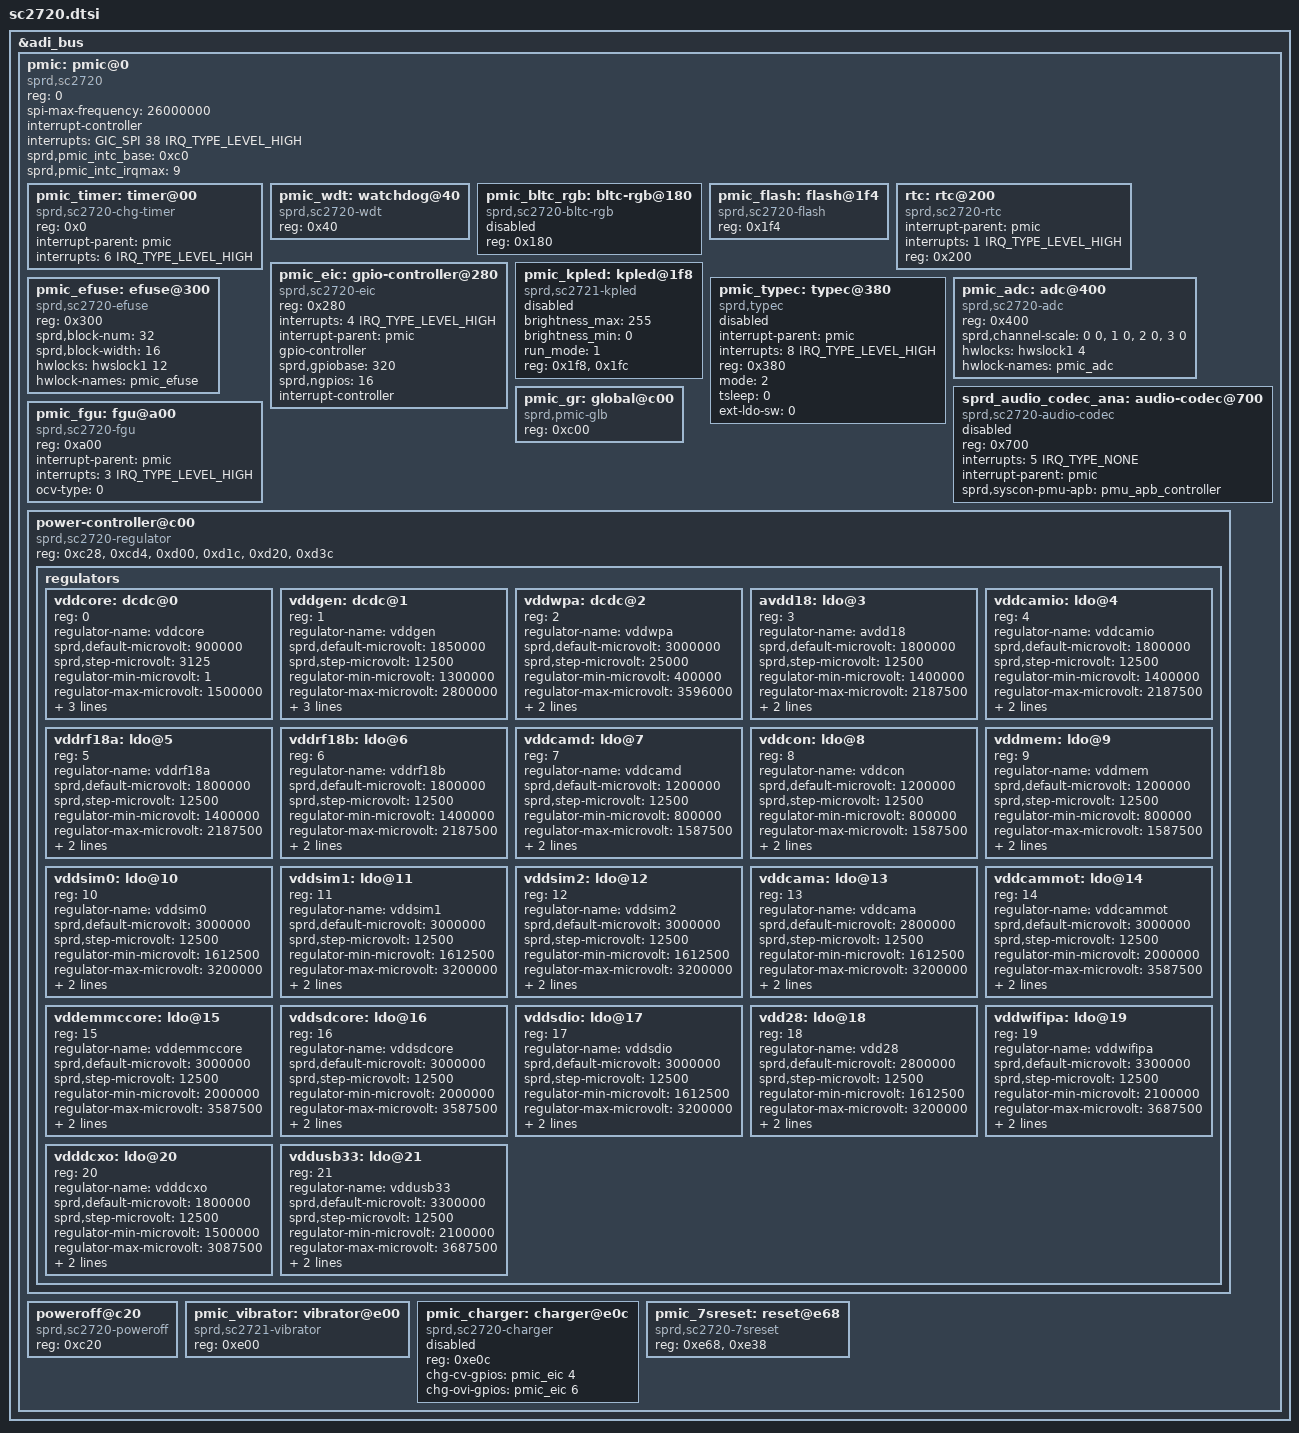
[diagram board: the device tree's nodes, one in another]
/*
 * Spreadtrum Analog Die SC2720 DTS file
 *
 * Copyright (C) 2017, Spreadtrum Communications Inc.
 *
 * This file is licensed under a dual GPLv2 or X11 license.
 */

&adi_bus {
	pmic: pmic@0 {
		compatible = "sprd,sc2720";
		reg = <0>; /* chip select 0 */
		spi-max-frequency = <26000000>;
		#address-cells = <1>;
		#size-cells = <0>;
		interrupt-controller;
		#interrupt-cells = <2>;
		interrupts = <GIC_SPI 38 IRQ_TYPE_LEVEL_HIGH>;
		sprd,pmic_intc_base = <0xc0>;
		sprd,pmic_intc_irqmax = <9>;

		pmic_timer: timer@00 {
			compatible = "sprd,sc2720-chg-timer";
			reg = <0x0>;
			interrupt-parent = <&pmic>;
			interrupts = <6 IRQ_TYPE_LEVEL_HIGH>;
		};

		pmic_wdt: watchdog@40 {
			compatible = "sprd,sc2720-wdt";
			reg = <0x40>;
		};

		pmic_bltc_rgb: bltc-rgb@180 {
			compatible = "sprd,sc2720-bltc-rgb";
			reg = <0x180>;
			status = "disabled";
		};

		pmic_flash: flash@1f4 {
			compatible = "sprd,sc2720-flash";
			reg = <0x1f4>;
			status = "okay";
		};

		rtc: rtc@200 {
			compatible = "sprd,sc2720-rtc";
			interrupt-parent = <&pmic>;
			interrupts = <1 IRQ_TYPE_LEVEL_HIGH>;
			reg = <0x200>;
		};

		pmic_eic: gpio-controller@280 {
			compatible = "sprd,sc2720-eic";
			reg = <0x280>;
			interrupts = <4 IRQ_TYPE_LEVEL_HIGH>;
			interrupt-parent = <&pmic>;
			gpio-controller;
			#gpio-cells = <2>;
			sprd,gpiobase = <320>;
			sprd,ngpios = <16>;
			interrupt-controller;
			#interrupt-cells = <2>;
		};

		pmic_kpled: kpled@1f8 {
			compatible = "sprd,sc2721-kpled";
			brightness_max = <255>;
			brightness_min = <0>;
			run_mode = <1>; /* default current mode */
			reg = <0x1f8>,<0x1fc>;
			status = "disabled";
		};

		pmic_efuse: efuse@300 {
			compatible = "sprd,sc2720-efuse";
			reg = <0x300>;
			sprd,block-num = <32>;
			sprd,block-width = <16>;
			hwlocks = <&hwslock1 12>;
			hwlock-names = "pmic_efuse";
		};

		pmic_typec: typec@380 {
		    compatible = "sprd,typec";
		    interrupt-parent = <&pmic>;
		    interrupts = <8 IRQ_TYPE_LEVEL_HIGH>;
		    reg = <0x380>;
		    mode = <2>;
		    tsleep = <0>;
		    ext-ldo-sw = <0>;
		    status = "disabled";
		};

		pmic_adc: adc@400{
			compatible = "sprd,sc2720-adc";
			reg = <0x400>;
			#io-channel-cells = <1>;
			sprd,channel-scale = <0 0>, <1 0>, <2 0>, <3 0>;
			hwlocks = <&hwslock1 4>;
			hwlock-names = "pmic_adc";
		};

		sprd_audio_codec_ana: audio-codec@700 {
			compatible = "sprd,sc2720-audio-codec";
			#sound-dai-cells = <1>;
			reg = <0x700>;
			interrupts = <5 IRQ_TYPE_NONE>;
			interrupt-parent = <&pmic>;
			sprd,syscon-pmu-apb = <&pmu_apb_controller>;
			status = "disabled";
		};

		pmic_fgu: fgu@a00 {
			compatible = "sprd,sc2720-fgu";
			reg = <0xa00>;
			interrupt-parent = <&pmic>;
			interrupts = <3 IRQ_TYPE_LEVEL_HIGH>;
			ocv-type = <0>;
		};

		pmic_gr: global@c00 {
			compatible = "sprd,pmic-glb";
			reg = <0xc00>;
		};

		power-controller@c00 {
			compatible = "sprd,sc2720-regulator";
			reg = <0xc28>,<0xcd4>,<0xd00>,<0xd1c>,<0xd20>,<0xd3c>;

			regulators {
				#address-cells = <1>;
				#size-cells = <0>;

				vddcore: dcdc@0 {
					reg = <0>;
					regulator-name = "vddcore";
					sprd,default-microvolt = <900000>;
					sprd,step-microvolt = <3125>;
					regulator-min-microvolt = <1>;
					regulator-max-microvolt = <1500000>;
					regulator-microvolt-offset = <0>;
					sprd,hide-offset = <1000>;
					sprd,default-on;
				};

				vddgen: dcdc@1 {
					reg = <1>;
					regulator-name = "vddgen";
					sprd,default-microvolt = <1850000>;
					sprd,step-microvolt = <12500>;
					regulator-min-microvolt = <1300000>;
					regulator-max-microvolt = <2800000>;
					regulator-microvolt-offset = <0>;
					sprd,hide-offset = <1000>;
					sprd,default-on;
				};

				vddwpa: dcdc@2 {
					reg = <2>;
					regulator-name = "vddwpa";
					sprd,default-microvolt = <3000000>;
					sprd,step-microvolt = <25000>;
					regulator-min-microvolt = <400000>;
					regulator-max-microvolt = <3596000>;
					regulator-microvolt-offset = <0>;
					sprd,hide-offset = <1000>;
				};

				avdd18: ldo@3 {
					reg = <3>;
					regulator-name = "avdd18";
					sprd,default-microvolt = <1800000>;
					sprd,step-microvolt = <12500>;
					regulator-min-microvolt = <1400000>;
					regulator-max-microvolt = <2187500>;
					regulator-microvolt-offset = <0>;
					sprd,hide-offset = <1000>;
				};

				vddcamio: ldo@4 {
					reg = <4>;
					regulator-name = "vddcamio";
					sprd,default-microvolt = <1800000>;
					sprd,step-microvolt = <12500>;
					regulator-min-microvolt = <1400000>;
					regulator-max-microvolt = <2187500>;
					regulator-microvolt-offset = <0>;
					sprd,hide-offset = <1000>;
				};

				vddrf18a: ldo@5 {
					reg = <5>;
					regulator-name = "vddrf18a";
					sprd,default-microvolt = <1800000>;
					sprd,step-microvolt = <12500>;
					regulator-min-microvolt = <1400000>;
					regulator-max-microvolt = <2187500>;
					regulator-microvolt-offset = <0>;
					sprd,hide-offset = <1000>;
				};

				vddrf18b: ldo@6 {
					reg = <6>;
					regulator-name = "vddrf18b";
					sprd,default-microvolt = <1800000>;
					sprd,step-microvolt = <12500>;
					regulator-min-microvolt = <1400000>;
					regulator-max-microvolt = <2187500>;
					regulator-microvolt-offset = <0>;
					sprd,hide-offset = <1000>;
				};

				vddcamd: ldo@7 {
					reg = <7>;
					regulator-name = "vddcamd";
					sprd,default-microvolt = <1200000>;
					sprd,step-microvolt = <12500>;
					regulator-min-microvolt = <800000>;
					regulator-max-microvolt = <1587500>;
					regulator-microvolt-offset = <0>;
					sprd,hide-offset = <1000>;
				};

				vddcon: ldo@8 {
					reg = <8>;
					regulator-name = "vddcon";
					sprd,default-microvolt = <1200000>;
					sprd,step-microvolt = <12500>;
					regulator-min-microvolt = <800000>;
					regulator-max-microvolt = <1587500>;
					regulator-microvolt-offset = <0>;
					sprd,hide-offset = <1000>;
				};

				vddmem: ldo@9 {
					reg = <9>;
					regulator-name = "vddmem";
					sprd,default-microvolt = <1200000>;
					sprd,step-microvolt = <12500>;
					regulator-min-microvolt = <800000>;
					regulator-max-microvolt = <1587500>;
					regulator-microvolt-offset = <0>;
					sprd,hide-offset = <1000>;
				};

				vddsim0: ldo@10 {
					reg = <10>;
					regulator-name = "vddsim0";
					sprd,default-microvolt = <3000000>;
					sprd,step-microvolt = <12500>;
					regulator-min-microvolt = <1612500>;
					regulator-max-microvolt = <3200000>;
					regulator-microvolt-offset = <0>;
					sprd,hide-offset = <1000>;
				};

				vddsim1: ldo@11 {
					reg = <11>;
					regulator-name = "vddsim1";
					sprd,default-microvolt = <3000000>;
					sprd,step-microvolt = <12500>;
					regulator-min-microvolt = <1612500>;
					regulator-max-microvolt = <3200000>;
					regulator-microvolt-offset = <0>;
					sprd,hide-offset = <1000>;
				};

				vddsim2: ldo@12 {
					reg = <12>;
					regulator-name = "vddsim2";
					sprd,default-microvolt = <3000000>;
					sprd,step-microvolt = <12500>;
					regulator-min-microvolt = <1612500>;
					regulator-max-microvolt = <3200000>;
					regulator-microvolt-offset = <0>;
					sprd,hide-offset = <1000>;
				};

				vddcama: ldo@13 {
					reg = <13>;
					regulator-name = "vddcama";
					sprd,default-microvolt = <2800000>;
					sprd,step-microvolt = <12500>;
					regulator-min-microvolt = <1612500>;
					regulator-max-microvolt = <3200000>;
					regulator-microvolt-offset = <0>;
					sprd,hide-offset = <1000>;
				};

				vddcammot: ldo@14 {
					reg = <14>;
					regulator-name = "vddcammot";
					sprd,default-microvolt = <3000000>;
					sprd,step-microvolt = <12500>;
					regulator-min-microvolt = <2000000>;
					regulator-max-microvolt = <3587500>;
					regulator-microvolt-offset = <0>;
					sprd,hide-offset = <1000>;
				};

				vddemmccore: ldo@15 {
					reg = <15>;
					regulator-name = "vddemmccore";
					sprd,default-microvolt = <3000000>;
					sprd,step-microvolt = <12500>;
					regulator-min-microvolt = <2000000>;
					regulator-max-microvolt = <3587500>;
					regulator-microvolt-offset = <0>;
					sprd,hide-offset = <1000>;
				};

				vddsdcore: ldo@16 {
					reg = <16>;
					regulator-name = "vddsdcore";
					sprd,default-microvolt = <3000000>;
					sprd,step-microvolt = <12500>;
					regulator-min-microvolt = <2000000>;
					regulator-max-microvolt = <3587500>;
					regulator-microvolt-offset = <0>;
					sprd,hide-offset = <1000>;
				};

				vddsdio: ldo@17 {
					reg = <17>;
					regulator-name = "vddsdio";
					sprd,default-microvolt = <3000000>;
					sprd,step-microvolt = <12500>;
					regulator-min-microvolt = <1612500>;
					regulator-max-microvolt = <3200000>;
					regulator-microvolt-offset = <0>;
					sprd,hide-offset = <1000>;
				};

				vdd28: ldo@18 {
					reg = <18>;
					regulator-name = "vdd28";
					sprd,default-microvolt = <2800000>;
					sprd,step-microvolt = <12500>;
					regulator-min-microvolt = <1612500>;
					regulator-max-microvolt = <3200000>;
					regulator-microvolt-offset = <0>;
					sprd,hide-offset = <1000>;
				};

				vddwifipa: ldo@19 {
					reg = <19>;
					regulator-name = "vddwifipa";
					sprd,default-microvolt = <3300000>;
					sprd,step-microvolt = <12500>;
					regulator-min-microvolt = <2100000>;
					regulator-max-microvolt = <3687500>;
					regulator-microvolt-offset = <0>;
					sprd,hide-offset = <1000>;
				};

				vdddcxo: ldo@20 {
					reg = <20>;
					regulator-name = "vdddcxo";
					sprd,default-microvolt = <1800000>;
					sprd,step-microvolt = <12500>;
					regulator-min-microvolt = <1500000>;
					regulator-max-microvolt = <3087500>;
					regulator-microvolt-offset = <0>;
					sprd,hide-offset = <1000>;
				};

				vddusb33: ldo@21 {
					reg = <21>;
					regulator-name = "vddusb33";
					sprd,default-microvolt = <3300000>;
					sprd,step-microvolt = <12500>;
					regulator-min-microvolt = <2100000>;
					regulator-max-microvolt = <3687500>;
					regulator-microvolt-offset = <0>;
					sprd,hide-offset = <1000>;
				};
			};
		};

		poweroff@c20 {
			compatible = "sprd,sc2720-poweroff";
			reg = <0xc20>;
		};

		pmic_vibrator: vibrator@e00 {
			compatible = "sprd,sc2721-vibrator";
			reg = <0xe00>;
		};

		pmic_charger: charger@e0c {
			compatible = "sprd,sc2720-charger";
			reg = <0xe0c>;
			chg-cv-gpios = <&pmic_eic 4 0>;
			chg-ovi-gpios = <&pmic_eic 6 0>;
			status = "disabled";
		};

		pmic_7sreset: reset@e68 {
			compatible = "sprd,sc2720-7sreset";
			reg = <0xe68>,<0xe38>;
		};
	};
};
